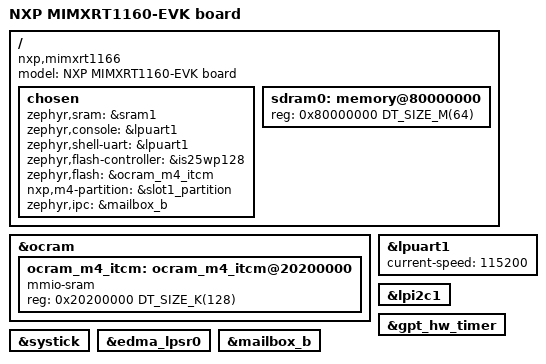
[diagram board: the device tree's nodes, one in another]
/*
 * Copyright (c) 2021, NXP
 *
 * SPDX-License-Identifier: Apache-2.0
 */

/dts-v1/;

#include <nxp/nxp_rt1160_cm4.dtsi>
#include "mimxrt1160_evk.dtsi"

/ {
	model = "NXP MIMXRT1160-EVK board";
	compatible = "nxp,mimxrt1166";

	chosen {
		/*
		 * Note: when using DMA, the SRAM region must be set to
		 * a memory region that is not cached by the chip. If the chosen
		 * sram region is changed and DMA is in use, you will
		 * encounter issues!
		 */
		zephyr,sram = &sram1;
		zephyr,console = &lpuart1;
		zephyr,shell-uart = &lpuart1;
		zephyr,flash-controller = &is25wp128;
		zephyr,flash = &ocram_m4_itcm;
		nxp,m4-partition = &slot1_partition;
		zephyr,ipc = &mailbox_b;
	};

	sdram0: memory@80000000 {
		/* Winbond W9825G6KH-5I */
		device_type = "memory";
		reg = <0x80000000 DT_SIZE_M(64)>;
	};
};

&ocram {
	#address-cells = <1>;
	#size-cells = <1>;

	/* The M7 core accesses the M4 TCMs through the OCRAM alias.
	 * Add an OCRAM alias region just for the M4 ITCM.  The M4
	 * memory map:
	 *	0x1FFE_0000 - 0x1FFF_FFFF: ITCM/RAM_L/sram0, OCRAM 0x2020_0000
	 *	0x2000_0000 - 0x2001_FFFF: DTCM/RAM_U/sram1, OCRAM 0x2022_0000
	 *
	 * The M7 core can access this OCRAM alias for M4 ITCM and copy
	 * the M4 image here.
	 */
	ocram_m4_itcm: ocram_m4_itcm@20200000 {
		compatible = "mmio-sram";
		reg = <0x20200000 DT_SIZE_K(128)>;
	};
};

&lpuart1 {
	status = "okay";
	current-speed = <115200>;
};

&lpi2c1 {
	status = "okay";
};

/* GPT and Systick are enabled. If power management is enabled, the GPT
 * timer will be used instead of systick, as allows the core clock to
 * be gated.
 */
&gpt_hw_timer {
	status = "okay";
};

&systick {
	status = "okay";
};

&edma_lpsr0 {
	status = "okay";
};

&mailbox_b {
	status = "okay";
};
